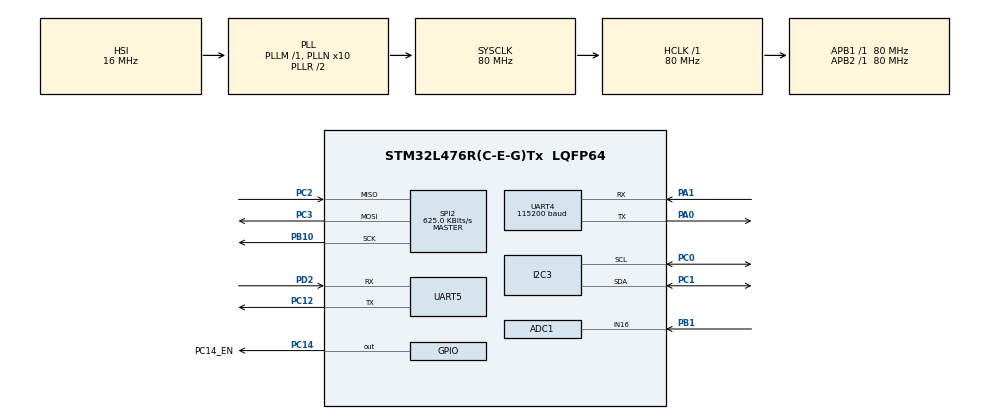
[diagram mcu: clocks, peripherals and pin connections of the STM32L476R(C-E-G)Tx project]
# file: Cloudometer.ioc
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ADC1.Channel-0\#ChannelRegularConversion=ADC_CHANNEL_16
ADC1.NbrOfConversionFlag=1
ADC1.OffsetNumber-0\#ChannelRegularConversion=ADC_OFFSET_NONE
ADC1.Rank-0\#ChannelRegularConversion=1
ADC1.SamplingTime-0\#ChannelRegularConversion=ADC_SAMPLETIME_2CYCLES_5
ADC1.master=1
Dma.Request0=UART5_RX
Dma.UART5_RX.0.Direction=DMA_PERIPH_TO_MEMORY
Dma.UART5_RX.0.Instance=DMA2_Channel2
Dma.UART5_RX.0.MemDataAlignment=DMA_MDATAALIGN_BYTE
Dma.UART5_RX.0.MemInc=DMA_MINC_ENABLE
Dma.UART5_RX.0.Mode=DMA_CIRCULAR
Dma.UART5_RX.0.PeriphDataAlignment=DMA_PDATAALIGN_BYTE
Dma.UART5_RX.0.PeriphInc=DMA_PINC_DISABLE
Dma.UART5_RX.0.Priority=DMA_PRIORITY_LOW
I2C3.Timing=0x10909CEC
Mcu.Family=STM32L4
Mcu.Name=STM32L476R(C-E-G)Tx
Mcu.Package=LQFP64
NVIC.DMA2_Channel2_IRQn=true\:0\:0\:false\:true\:true\:2\:false\:true\:true
NVIC.PriorityGroup=NVIC_PRIORITYGROUP_4
NVIC.UART4_IRQn=true\:0\:0\:false\:false\:true\:true\:true\:true
NVIC.UART5_IRQn=true\:0\:0\:false\:true\:true\:1\:true\:true\:true
PA0.Mode=Asynchronous
PA0.Signal=UART4_TX
PA1.Mode=Asynchronous
PA1.Signal=UART4_RX
PB1.Signal=ADCx_IN16
PB10.Mode=Full_Duplex_Master
PB10.Signal=SPI2_SCK
PC0.Mode=I2C
PC0.Signal=I2C3_SCL
PC1.Mode=I2C
PC1.Signal=I2C3_SDA
PC12.Mode=Asynchronous
PC12.Signal=UART5_TX
PC14-OSC32_IN\ (PC14).GPIO_Label=PC14_EN
PC14-OSC32_IN\ (PC14).PinState=GPIO_PIN_SET
PC14-OSC32_IN\ (PC14).Signal=GPIO_Output
PC2.Mode=Full_Duplex_Master
PC2.Signal=SPI2_MISO
PC3.Mode=Full_Duplex_Master
PC3.Signal=SPI2_MOSI
PD2.GPIO_PuPd=GPIO_PULLUP
PD2.Mode=Asynchronous
PD2.Signal=UART5_RX
ProjectManager.HeapSize=0x200
ProjectManager.StackSize=0x400
ProjectManager.TargetToolchain=STM32CubeIDE
RCC.ADCFreq_Value=64000000
RCC.AHBFreq_Value=80000000
RCC.APB1Freq_Value=80000000
RCC.APB1TimFreq_Value=80000000
RCC.APB2Freq_Value=80000000
RCC.APB2TimFreq_Value=80000000
RCC.CortexFreq_Value=80000000
RCC.HCLKFreq_Value=80000000
RCC.HSE_VALUE=8000000
RCC.HSI_VALUE=16000000
RCC.LSE_VALUE=32768
RCC.MSI_VALUE=4000000
RCC.PLLN=10
RCC.PLLSourceVirtual=RCC_PLLSOURCE_HSI
RCC.SYSCLKFreq_VALUE=80000000
RCC.SYSCLKSource=RCC_SYSCLKSOURCE_PLLCLK
RCC.USBFreq_Value=64000000
RCC.VCOOutputFreq_Value=160000000
SH.ADCx_IN16.0=ADC1_IN16,IN16-Single-Ended
SPI2.BaudRatePrescaler=SPI_BAUDRATEPRESCALER_128
SPI2.CLKPhase=SPI_PHASE_2EDGE
SPI2.CRCCalculation=SPI_CRCCALCULATION_DISABLE
SPI2.CalculateBaudRate=625.0 KBits/s
SPI2.DataSize=SPI_DATASIZE_16BIT
SPI2.Direction=SPI_DIRECTION_2LINES
SPI2.FirstBit=SPI_FIRSTBIT_LSB
SPI2.Mode=SPI_MODE_MASTER
SPI2.VirtualType=VM_MASTER
UART4.BaudRate=115200
board=custom

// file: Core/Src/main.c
/* USER CODE BEGIN Header */
/**
  ******************************************************************************
  * @file           : main.c
  * @brief          : Main program body
  ******************************************************************************
  * @attention
  *
  * <h2><center>&copy; Copyright (c) 2022 STMicroelectronics.
  * All rights reserved.</center></h2>
  *
  * This software component is licensed by ST under BSD 3-Clause license,
  * the "License"; You may not use this file except in compliance with the
  * License. You may obtain a copy of the License at:
  *                        opensource.org/licenses/BSD-3-Clause
  *
  ******************************************************************************
  */
/* USER CODE END Header */
#include "main.h"
#include "adc.h"
#include "dma.h"
#include "i2c.h"
#include "spi.h"
#include "usart.h"
#include "gpio.h"

/* USER CODE BEGIN PTD */
#undef RUN_TEST_PROGRAM			//Define if running testprogram

/* USER CODE END PTD */

void SystemClock_Config(void);

int main(void)
{

  /* MCU Configuration--------------------------------------------------------*/

  /* Reset of all peripherals, Initializes the Flash interface and the Systick. */
  HAL_Init();

  /* Configure the system clock */
  SystemClock_Config();

  /* Initialize all configured peripherals */
  MX_GPIO_Init();
  MX_ADC1_Init();
  MX_SPI2_Init();
  MX_UART5_Init();
  MX_DMA_Init();
  MX_I2C3_Init();
  MX_UART4_Init();
  /* USER CODE BEGIN 2 */
#ifdef RUN_TEST_PROGRAM
  Test_program();
#else
  // Run program
#endif
  //Initialize required sensors and wifi
  //This is done once
  sensorStartup();
  wifiStartup();

  /* USER CODE END 2 */

  /* Infinite loop */
  /* USER CODE BEGIN WHILE */
  while (1)
  {
	  connectToServer();
	  uploadTemp();
//	  discFromServer();		//Needed if server doesn't disconnect

	  //Upload to server interval
	  HAL_Delay(1000);
    /* USER CODE END WHILE */

  }
}

void SystemClock_Config(void)
{
  RCC_OscInitTypeDef RCC_OscInitStruct = {0};
  RCC_ClkInitTypeDef RCC_ClkInitStruct = {0};

  /** Configure the main internal regulator output voltage
  */
  if (HAL_PWREx_ControlVoltageScaling(PWR_REGULATOR_VOLTAGE_SCALE1) != HAL_OK)
  {
    Error_Handler();
  }

  /** Initializes the RCC Oscillators according to the specified parameters
  * in the RCC_OscInitTypeDef structure.
  */
  RCC_OscInitStruct.OscillatorType = RCC_OSCILLATORTYPE_HSI;
  RCC_OscInitStruct.HSIState = RCC_HSI_ON;
  RCC_OscInitStruct.HSICalibrationValue = RCC_HSICALIBRATION_DEFAULT;
  RCC_OscInitStruct.PLL.PLLState = RCC_PLL_ON;
  RCC_OscInitStruct.PLL.PLLSource = RCC_PLLSOURCE_HSI;
  RCC_OscInitStruct.PLL.PLLM = 1;
  RCC_OscInitStruct.PLL.PLLN = 10;
  RCC_OscInitStruct.PLL.PLLP = RCC_PLLP_DIV7;
  RCC_OscInitStruct.PLL.PLLQ = RCC_PLLQ_DIV2;
  RCC_OscInitStruct.PLL.PLLR = RCC_PLLR_DIV2;
  if (HAL_RCC_OscConfig(&RCC_OscInitStruct) != HAL_OK)
  {
    Error_Handler();
  }

  /** Initializes the CPU, AHB and APB buses clocks
  */
  RCC_ClkInitStruct.ClockType = RCC_CLOCKTYPE_HCLK|RCC_CLOCKTYPE_SYSCLK
                              |RCC_CLOCKTYPE_PCLK1|RCC_CLOCKTYPE_PCLK2;
  RCC_ClkInitStruct.SYSCLKSource = RCC_SYSCLKSOURCE_PLLCLK;
  RCC_ClkInitStruct.AHBCLKDivider = RCC_SYSCLK_DIV1;
  RCC_ClkInitStruct.APB1CLKDivider = RCC_HCLK_DIV1;
  RCC_ClkInitStruct.APB2CLKDivider = RCC_HCLK_DIV1;

  if (HAL_RCC_ClockConfig(&RCC_ClkInitStruct, FLASH_LATENCY_4) != HAL_OK)
  {
    Error_Handler();
  }
}

void Error_Handler(void)
{
  __disable_irq();
  while (1)
  {
  }
}
